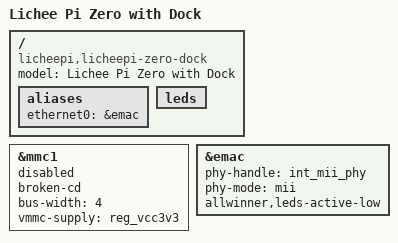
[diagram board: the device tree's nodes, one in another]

#include "sun8i-v3s-licheepi-zero.dts"
#include <dt-bindings/input/input.h>

/ {
	model = "Lichee Pi Zero with Dock";
	compatible = "licheepi,licheepi-zero-dock", "licheepi,licheepi-zero",
		     "allwinner,sun8i-v3s";
	aliases {
		ethernet0 = &emac;
	};

	leds {
		// note: LED pins conflict with MMC1, so only 1 can be used
		status = "okay";
	};
};

&mmc1 {
	broken-cd;
	bus-width = <4>;
	vmmc-supply = <&reg_vcc3v3>;
	status = "disabled";
};

/*
&codec {
	allwinner,audio-routing =
		"Headphone", "HP",
		"Headphone", "HPCOM",
		"MIC1", "Mic",
		"Mic",  "HBIAS";
	status = "okay";
};
*/

&emac {
	phy-handle = <&int_mii_phy>;
	phy-mode = "mii";
	allwinner,leds-active-low;
	status = "okay";
};

/*
&lradc {
	vref-supply = <&reg_vcc3v0>;
	status = "okay";

	button-200 {
		label = "Up";
		linux,code = <KEY_VOLUMEUP>;
		channel = <0>;
		voltage = <200000>;
	};

	button-400 {
		label = "Down";
		linux,code = <KEY_VOLUMEDOWN>;
		channel = <0>;
		voltage = <400000>;
	};

	button-600 {
		label = "Select";
		linux,code = <KEY_SELECT>;
		channel = <0>;
		voltage = <600000>;
	};

	button-800 {
		label = "OK";
		linux,code = <KEY_OK>;
		channel = <0>;
		voltage = <800000>;
	};
};
*/

